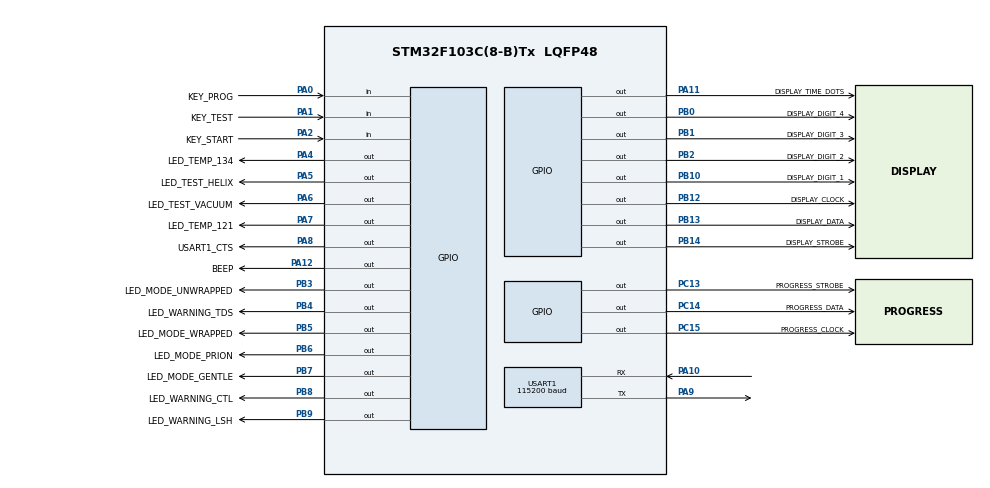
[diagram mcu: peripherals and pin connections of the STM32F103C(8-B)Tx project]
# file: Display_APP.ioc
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Dma.Request0=USART1_RX
Dma.USART1_RX.0.Direction=DMA_PERIPH_TO_MEMORY
Dma.USART1_RX.0.Instance=DMA1_Channel5
Dma.USART1_RX.0.MemDataAlignment=DMA_MDATAALIGN_BYTE
Dma.USART1_RX.0.MemInc=DMA_MINC_ENABLE
Dma.USART1_RX.0.Mode=DMA_NORMAL
Dma.USART1_RX.0.PeriphDataAlignment=DMA_PDATAALIGN_BYTE
Dma.USART1_RX.0.PeriphInc=DMA_PINC_DISABLE
Dma.USART1_RX.0.Priority=DMA_PRIORITY_HIGH
FREERTOS.Queues01=serialRxQueue,3,30,1,Dynamic,NULL,NULL
FREERTOS.Tasks01=taskMain,0,1024,TaskMain,Default,NULL,Dynamic,NULL,NULL
FREERTOS.configTOTAL_HEAP_SIZE=10240
FREERTOS.configUSE_NEWLIB_REENTRANT=1
Mcu.Family=STM32F1
Mcu.Name=STM32F103C(8-B)Tx
Mcu.Package=LQFP48
NVIC.DMA1_Channel5_IRQn=true\:5\:0\:false\:false\:true\:true\:false\:true\:true
NVIC.PriorityGroup=NVIC_PRIORITYGROUP_4
NVIC.TIM4_IRQn=true\:0\:0\:true\:false\:true\:false\:false\:true\:true
NVIC.TimeBase=TIM4_IRQn
NVIC.TimeBaseIP=TIM4
PA0-WKUP.GPIO_Label=KEY_PROG
PA0-WKUP.Signal=GPIO_Input
PA1.GPIO_Label=KEY_TEST
PA1.Signal=GPIO_Input
PA10.Mode=Asynchronous
PA10.Signal=USART1_RX
PA11.GPIO_Label=DISPLAY_TIME_DOTS
PA11.Signal=GPIO_Output
PA12.GPIO_Label=BEEP
PA12.Signal=GPIO_Output
PA13.Mode=Serial_Wire
PA13.Signal=SYS_JTMS-SWDIO
PA14.Mode=Serial_Wire
PA14.Signal=SYS_JTCK-SWCLK
PA2.GPIO_Label=KEY_START
PA2.Signal=GPIO_Input
PA4.GPIO_Label=LED_TEMP_134
PA4.Signal=GPIO_Output
PA5.GPIO_Label=LED_TEST_HELIX
PA5.Signal=GPIO_Output
PA6.GPIO_Label=LED_TEST_VACUUM
PA6.Signal=GPIO_Output
PA7.GPIO_Label=LED_TEMP_121
PA7.Signal=GPIO_Output
PA8.GPIO_Label=USART1_CTS
PA8.Signal=GPIO_Output
PA9.Mode=Asynchronous
PA9.Signal=USART1_TX
PB0.GPIO_Label=DISPLAY_DIGIT_4
PB0.Signal=GPIO_Output
PB1.GPIO_Label=DISPLAY_DIGIT_3
PB1.Signal=GPIO_Output
PB10.GPIO_Label=DISPLAY_DIGIT_1
PB10.Signal=GPIO_Output
PB12.GPIO_Label=DISPLAY_CLOCK
PB12.Signal=GPIO_Output
PB13.GPIO_Label=DISPLAY_DATA
PB13.Signal=GPIO_Output
PB14.GPIO_Label=DISPLAY_STROBE
PB14.Signal=GPIO_Output
PB2.GPIO_Label=DISPLAY_DIGIT_2
PB2.Signal=GPIO_Output
PB3.GPIO_Label=LED_MODE_UNWRAPPED
PB3.Signal=GPIO_Output
PB4.GPIO_Label=LED_WARNING_TDS
PB4.Signal=GPIO_Output
PB5.GPIO_Label=LED_MODE_WRAPPED
PB5.Signal=GPIO_Output
PB6.GPIO_Label=LED_MODE_PRION
PB6.Signal=GPIO_Output
PB7.GPIO_Label=LED_MODE_GENTLE
PB7.Signal=GPIO_Output
PB8.GPIO_Label=LED_WARNING_CTL
PB8.Signal=GPIO_Output
PB9.GPIO_Label=LED_WARNING_LSH
PB9.Signal=GPIO_Output
PC13-TAMPER-RTC.GPIO_Label=PROGRESS_STROBE
PC13-TAMPER-RTC.Signal=GPIO_Output
PC14-OSC32_IN.GPIO_Label=PROGRESS_DATA
PC14-OSC32_IN.Signal=GPIO_Output
PC15-OSC32_OUT.GPIO_Label=PROGRESS_CLOCK
PC15-OSC32_OUT.Signal=GPIO_Output
ProjectManager.HeapSize=0x200
ProjectManager.StackSize=0x400
ProjectManager.TargetToolchain=STM32CubeIDE
RCC.APB1Freq_Value=8000000
RCC.APB2Freq_Value=8000000
USART1.BaudRate=115200
USART1.VirtualMode=VM_ASYNC
VP_FREERTOS_VS_CMSIS_V1.Mode=CMSIS_V1
VP_SYS_VS_tim4.Mode=TIM4
board=custom

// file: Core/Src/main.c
/* USER CODE BEGIN Header */
/**
  ******************************************************************************
  * @file           : main.c
  * @brief          : Main program body
  ******************************************************************************
  * @attention
  *
  * Copyright (c) 2022 STMicroelectronics.
  * All rights reserved.
  *
  * This software is licensed under terms that can be found in the LICENSE file
  * in the root directory of this software component.
  * If no LICENSE file comes with this software, it is provided AS-IS.
  *
  ******************************************************************************
  */
/* USER CODE END Header */
#include "main.h"
#include "cmsis_os.h"

/* USER CODE BEGIN Includes */

#include "globals.h"

/* USER CODE END Includes */

UART_HandleTypeDef huart1;
DMA_HandleTypeDef hdma_usart1_rx;

osThreadId taskMainHandle;
osMessageQId serialRxQueueHandle;

void SystemClock_Config(void);
static void MX_GPIO_Init(void);
static void MX_DMA_Init(void);
static void MX_USART1_UART_Init(void);
void TaskMain(void const * argument);

/* USER CODE BEGIN 0 */

//void HAL_UARTEx_RxEventCallback(UART_HandleTypeDef *huart, uint16_t Size) {
//	//HAL_UART_Receive_DMA(p_activeUART, UART_rxBuffer, 3);
//
//	// Check for UART
//	if (huart->Instance == huart1.Instance) {
//		PanelSerialReceive(UART_rxBuffer, Size);
//	}
//
//	// Receive again
//	HAL_UARTEx_ReceiveToIdle_DMA(huart, UART_rxBuffer, UART_BUFFER_SIZE); // Interrupt on receive buffer full or idle (end receive)
//	__HAL_DMA_DISABLE_IT(&hdma_usart1_rx, DMA_IT_HT); // Disable half buffer received interrupt
//
//}
//
//void HAL_UART_RxCpltCallback(UART_HandleTypeDef *huart)
//{
//	if (huart->Instance == huart1.Instance) {
//		PanelSerialReceive(UART_rxBuffer, UART_BUFFER_SIZE);
//	}
//
//	HAL_UART_Receive_DMA(huart, UART_rxBuffer, UART_BUFFER_SIZE);
//	__HAL_DMA_DISABLE_IT(&hdma_usart1_rx, DMA_IT_HT);
//}

/* USER CODE END 0 */

int main(void)
{

  /* MCU Configuration--------------------------------------------------------*/

  /* Reset of all peripherals, Initializes the Flash interface and the Systick. */
  HAL_Init();

  /* Configure the system clock */
  SystemClock_Config();

  /* Initialize all configured peripherals */
  MX_GPIO_Init();
  MX_DMA_Init();
  MX_USART1_UART_Init();

  /* Create the queue(s) */
  /* definition and creation of serialRxQueue */
  osMessageQDef(serialRxQueue, 3, 30);
  serialRxQueueHandle = osMessageCreate(osMessageQ(serialRxQueue), NULL);

  /* Create the thread(s) */
  /* definition and creation of taskMain */
  osThreadDef(taskMain, TaskMain, osPriorityNormal, 0, 512);
  taskMainHandle = osThreadCreate(osThread(taskMain), NULL);

  /* Start scheduler */
  osKernelStart();
  /* We should never get here as control is now taken by the scheduler */
  /* Infinite loop */
  while (1)
  {

  }
}

void SystemClock_Config(void)
{
  RCC_OscInitTypeDef RCC_OscInitStruct = {0};
  RCC_ClkInitTypeDef RCC_ClkInitStruct = {0};

  /** Initializes the RCC Oscillators according to the specified parameters
  * in the RCC_OscInitTypeDef structure.
  */
  RCC_OscInitStruct.OscillatorType = RCC_OSCILLATORTYPE_HSI;
  RCC_OscInitStruct.HSIState = RCC_HSI_ON;
  RCC_OscInitStruct.HSICalibrationValue = RCC_HSICALIBRATION_DEFAULT;
  RCC_OscInitStruct.PLL.PLLState = RCC_PLL_NONE;
  if (HAL_RCC_OscConfig(&RCC_OscInitStruct) != HAL_OK)
  {
    Error_Handler();
  }

  /** Initializes the CPU, AHB and APB buses clocks
  */
  RCC_ClkInitStruct.ClockType = RCC_CLOCKTYPE_HCLK|RCC_CLOCKTYPE_SYSCLK
                              |RCC_CLOCKTYPE_PCLK1|RCC_CLOCKTYPE_PCLK2;
  RCC_ClkInitStruct.SYSCLKSource = RCC_SYSCLKSOURCE_HSI;
  RCC_ClkInitStruct.AHBCLKDivider = RCC_SYSCLK_DIV1;
  RCC_ClkInitStruct.APB1CLKDivider = RCC_HCLK_DIV1;
  RCC_ClkInitStruct.APB2CLKDivider = RCC_HCLK_DIV1;

  if (HAL_RCC_ClockConfig(&RCC_ClkInitStruct, FLASH_LATENCY_0) != HAL_OK)
  {
    Error_Handler();
  }
}

static void MX_USART1_UART_Init(void)
{

  huart1.Instance = USART1;
  huart1.Init.BaudRate = 115200;
  huart1.Init.WordLength = UART_WORDLENGTH_8B;
  huart1.Init.StopBits = UART_STOPBITS_1;
  huart1.Init.Parity = UART_PARITY_NONE;
  huart1.Init.Mode = UART_MODE_TX_RX;
  huart1.Init.HwFlowCtl = UART_HWCONTROL_NONE;
  huart1.Init.OverSampling = UART_OVERSAMPLING_16;
  if (HAL_UART_Init(&huart1) != HAL_OK)
  {
    Error_Handler();
  }

}

static void MX_DMA_Init(void)
{

  /* DMA controller clock enable */
  __HAL_RCC_DMA1_CLK_ENABLE();

  /* DMA interrupt init */
  /* DMA1_Channel5_IRQn interrupt configuration */
  HAL_NVIC_SetPriority(DMA1_Channel5_IRQn, 5, 0);
  HAL_NVIC_EnableIRQ(DMA1_Channel5_IRQn);

}

static void MX_GPIO_Init(void)
{
  GPIO_InitTypeDef GPIO_InitStruct = {0};

  /* GPIO Ports Clock Enable */
  __HAL_RCC_GPIOC_CLK_ENABLE();
  __HAL_RCC_GPIOA_CLK_ENABLE();
  __HAL_RCC_GPIOB_CLK_ENABLE();

  /*Configure GPIO pin Output Level */
  HAL_GPIO_WritePin(GPIOC, PROGRESS_STROBE_Pin|PROGRESS_DATA_Pin|PROGRESS_CLOCK_Pin, GPIO_PIN_RESET);

  /*Configure GPIO pin Output Level */
  HAL_GPIO_WritePin(GPIOA, LED_TEMP_134_Pin|LED_TEST_HELIX_Pin|LED_TEST_VACUUM_Pin|LED_TEMP_121_Pin
                          |USART1_CTS_Pin|DISPLAY_TIME_DOTS_Pin|BEEP_Pin, GPIO_PIN_RESET);

  /*Configure GPIO pin Output Level */
  HAL_GPIO_WritePin(GPIOB, DISPLAY_DIGIT_4_Pin|DISPLAY_DIGIT_3_Pin|DISPLAY_DIGIT_2_Pin|DISPLAY_DIGIT_1_Pin
                          |DISPLAY_CLOCK_Pin|DISPLAY_DATA_Pin|DISPLAY_STROBE_Pin|LED_MODE_UNWRAPPED_Pin
                          |LED_WARNING_TDS_Pin|LED_MODE_WRAPPED_Pin|LED_MODE_PRION_Pin|LED_MODE_GENTLE_Pin
                          |LED_WARNING_CTL_Pin|LED_WARNING_LSH_Pin, GPIO_PIN_RESET);

  /*Configure GPIO pins : PROGRESS_STROBE_Pin PROGRESS_DATA_Pin PROGRESS_CLOCK_Pin */
  GPIO_InitStruct.Pin = PROGRESS_STROBE_Pin|PROGRESS_DATA_Pin|PROGRESS_CLOCK_Pin;
  GPIO_InitStruct.Mode = GPIO_MODE_OUTPUT_PP;
  GPIO_InitStruct.Pull = GPIO_NOPULL;
  GPIO_InitStruct.Speed = GPIO_SPEED_FREQ_LOW;
  HAL_GPIO_Init(GPIOC, &GPIO_InitStruct);

  /*Configure GPIO pins : KEY_PROG_Pin KEY_TEST_Pin KEY_START_Pin */
  GPIO_InitStruct.Pin = KEY_PROG_Pin|KEY_TEST_Pin|KEY_START_Pin;
  GPIO_InitStruct.Mode = GPIO_MODE_INPUT;
  GPIO_InitStruct.Pull = GPIO_NOPULL;
  HAL_GPIO_Init(GPIOA, &GPIO_InitStruct);

  /*Configure GPIO pins : LED_TEMP_134_Pin LED_TEST_HELIX_Pin LED_TEST_VACUUM_Pin LED_TEMP_121_Pin
                           USART1_CTS_Pin DISPLAY_TIME_DOTS_Pin BEEP_Pin */
  GPIO_InitStruct.Pin = LED_TEMP_134_Pin|LED_TEST_HELIX_Pin|LED_TEST_VACUUM_Pin|LED_TEMP_121_Pin
                          |USART1_CTS_Pin|DISPLAY_TIME_DOTS_Pin|BEEP_Pin;
  GPIO_InitStruct.Mode = GPIO_MODE_OUTPUT_PP;
  GPIO_InitStruct.Pull = GPIO_NOPULL;
  GPIO_InitStruct.Speed = GPIO_SPEED_FREQ_LOW;
  HAL_GPIO_Init(GPIOA, &GPIO_InitStruct);

  /*Configure GPIO pins : DISPLAY_DIGIT_4_Pin DISPLAY_DIGIT_3_Pin DISPLAY_DIGIT_2_Pin DISPLAY_DIGIT_1_Pin
                           DISPLAY_CLOCK_Pin DISPLAY_DATA_Pin DISPLAY_STROBE_Pin LED_MODE_UNWRAPPED_Pin
                           LED_WARNING_TDS_Pin LED_MODE_WRAPPED_Pin LED_MODE_PRION_Pin LED_MODE_GENTLE_Pin
                           LED_WARNING_CTL_Pin LED_WARNING_LSH_Pin */
  GPIO_InitStruct.Pin = DISPLAY_DIGIT_4_Pin|DISPLAY_DIGIT_3_Pin|DISPLAY_DIGIT_2_Pin|DISPLAY_DIGIT_1_Pin
                          |DISPLAY_CLOCK_Pin|DISPLAY_DATA_Pin|DISPLAY_STROBE_Pin|LED_MODE_UNWRAPPED_Pin
                          |LED_WARNING_TDS_Pin|LED_MODE_WRAPPED_Pin|LED_MODE_PRION_Pin|LED_MODE_GENTLE_Pin
                          |LED_WARNING_CTL_Pin|LED_WARNING_LSH_Pin;
  GPIO_InitStruct.Mode = GPIO_MODE_OUTPUT_PP;
  GPIO_InitStruct.Pull = GPIO_NOPULL;
  GPIO_InitStruct.Speed = GPIO_SPEED_FREQ_LOW;
  HAL_GPIO_Init(GPIOB, &GPIO_InitStruct);

}

void TaskMain(void const * argument)
{
  /* USER CODE BEGIN 5 */
	SysInit();

	/* Infinite loop */
	for(;;)
	{
		__NOP();
		osDelay(100);
	}

  /* USER CODE END 5 */
}

void HAL_TIM_PeriodElapsedCallback(TIM_HandleTypeDef *htim)
{
  if (htim->Instance == TIM4) {
    HAL_IncTick();
  }
}

void Error_Handler(void)
{
  __disable_irq();
  while (1)
  {
  }
}
